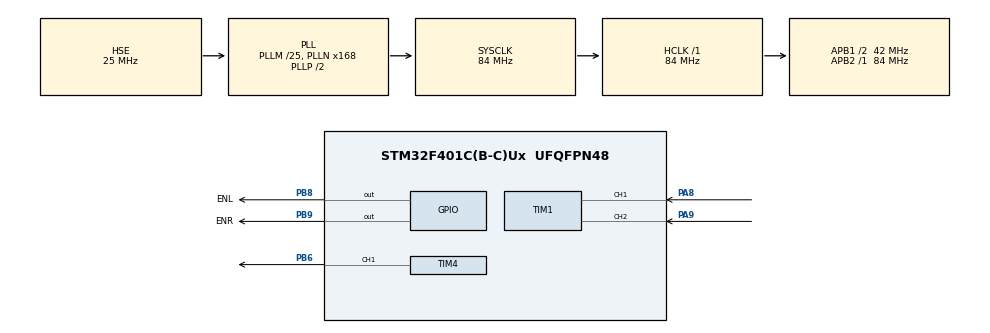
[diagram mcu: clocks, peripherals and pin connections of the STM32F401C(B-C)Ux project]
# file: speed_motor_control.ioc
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Mcu.Family=STM32F4
RCC.PLLSourceVirtual=RCC_PLLSOURCE_HSE
TIM4.Channel-PWM\ Generation1\ CH1=TIM_CHANNEL_1
RCC.CortexFreq_Value=84000000
PB9.GPIO_Label=ENR
Dma.TIM4_CH1.0.FIFOMode=DMA_FIFOMODE_DISABLE
PH1\ -\ OSC_OUT.Mode=HSE-External-Oscillator
RCC.APB1CLKDivider=RCC_HCLK_DIV2
PA9.GPIO_PuPd=GPIO_PULLUP
RCC.SYSCLKSource=RCC_SYSCLKSOURCE_PLLCLK
ProjectManager.StackSize=0x400
Dma.TIM4_CH1.0.PeriphInc=DMA_PINC_DISABLE
TIM3.Channel-Input_Capture1_from_TRC=TIM_CHANNEL_1
PA13.Signal=SYS_JTMS-SWDIO
PB8.GPIO_Label=ENL
PH0\ -\ OSC_IN.Mode=HSE-External-Oscillator
SH.S_TIM1_CH1.0=TIM1_CH1,Encoder_Interface
PH0\ -\ OSC_IN.Signal=RCC_OSC_IN
ProjectManager.TargetToolchain=STM32CubeIDE
RCC.HCLKFreq_Value=84000000
RCC.APB2TimFreq_Value=84000000
TIM3.Period=0xffff
PA9.Signal=S_TIM1_CH2
PB6.Signal=S_TIM4_CH1
TIM4.Prescaler=200-1
Dma.TIM4_CH1.0.Priority=DMA_PRIORITY_MEDIUM
RCC.LSE_VALUE=32768
RCC.AHBFreq_Value=84000000
RCC.HSE_VALUE=25000000
PH1\ -\ OSC_OUT.Signal=RCC_OSC_OUT
board=custom
RCC.VCOOutputFreq_Value=168000000
NVIC.TIM3_IRQn=true\:0\:0\:false\:false\:true\:true\:true
TIM1.TIM_MasterOutputTrigger=TIM_TRGO_OC1
RCC.APB2Freq_Value=84000000
Dma.TIM4_CH1.0.Instance=DMA1_Stream0
Dma.TIM4_CH1.0.MemInc=DMA_MINC_ENABLE
SH.S_TIM1_CH2.0=TIM1_CH2,Encoder_Interface
PA14.Mode=Serial_Wire
TIM3.Prescaler=16-1
PA8.Signal=S_TIM1_CH1
VP_TIM3_VS_CH1.Mode=Input_Capture1_from_TRC
Dma.TIM4_CH1.0.Direction=DMA_PERIPH_TO_MEMORY
TIM4.Period=100
VP_TIM3_VS_ClockSourceITR.Mode=TriggerSource_ITR0
PA13.Mode=Serial_Wire
Mcu.Name=STM32F401C(B-C)Ux
RCC.48MHZClocksFreq_Value=42000000
RCC.SYSCLKFreq_VALUE=84000000
Mcu.Package=UFQFPN48
PB9.Signal=GPIO_Output
Dma.TIM4_CH1.0.Mode=DMA_NORMAL
PA14.Signal=SYS_JTCK-SWCLK
ProjectManager.HeapSize=0x200
RCC.HSI_VALUE=16000000
PA8.GPIO_PuPd=GPIO_PULLUP
VP_TIM4_VS_ClockSourceINT.Mode=Internal
NVIC.PriorityGroup=NVIC_PRIORITYGROUP_4
PB9.GPIO_Speed=GPIO_SPEED_FREQ_HIGH
RCC.PLLM=25
RCC.PLLN=168
SH.S_TIM4_CH1.0=TIM4_CH1,PWM Generation1 CH1
RCC.APB1TimFreq_Value=84000000
PA9.GPIO_Speed=GPIO_SPEED_FREQ_HIGH
PB8.Signal=GPIO_Output
NVIC.DMA1_Stream0_IRQn=true\:0\:0\:false\:false\:true\:false\:true
Dma.Request0=TIM4_CH1
VP_TIM3_VS_ControllerModeReset.Mode=Reset Mode
RCC.APB1Freq_Value=42000000
PB8.GPIO_Speed=GPIO_SPEED_FREQ_HIGH
Dma.TIM4_CH1.0.MemDataAlignment=DMA_MDATAALIGN_HALFWORD
PA8.GPIO_Speed=GPIO_SPEED_FREQ_HIGH
VP_TIM3_VS_ClockSourceINT.Mode=Internal
Dma.TIM4_CH1.0.PeriphDataAlignment=DMA_PDATAALIGN_HALFWORD

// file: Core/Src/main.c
/* USER CODE BEGIN Header */
/**
  ******************************************************************************
  * @file           : main.c
  * @brief          : Main program body
  ******************************************************************************
  * @attention
  *
  * <h2><center>&copy; Copyright (c) 2021 STMicroelectronics.
  * All rights reserved.</center></h2>
  *
  * This software component is licensed by ST under BSD 3-Clause license,
  * the "License"; You may not use this file except in compliance with the
  * License. You may obtain a copy of the License at:
  *                        opensource.org/licenses/BSD-3-Clause
  *
  ******************************************************************************
  */
/* USER CODE END Header */
#include "main.h"

TIM_HandleTypeDef htim1;
TIM_HandleTypeDef htim3;
TIM_HandleTypeDef htim4;
DMA_HandleTypeDef hdma_tim4_ch1;

/* USER CODE BEGIN PV */
volatile int16_t konter;
volatile uint8_t dir,valpwm=20;
volatile uint32_t trig;
volatile float freq;
/* USER CODE END PV */

void SystemClock_Config(void);
static void MX_GPIO_Init(void);
static void MX_DMA_Init(void);
static void MX_TIM1_Init(void);
static void MX_TIM3_Init(void);
static void MX_TIM4_Init(void);

int main(void)
{

  /* MCU Configuration--------------------------------------------------------*/

  /* Reset of all peripherals, Initializes the Flash interface and the Systick. */
  HAL_Init();

  /* Configure the system clock */
  SystemClock_Config();

  /* Initialize all configured peripherals */
  MX_GPIO_Init();
  MX_DMA_Init();
  MX_TIM1_Init();
  MX_TIM3_Init();
  MX_TIM4_Init();
  /* USER CODE BEGIN 2 */
HAL_TIM_Encoder_Start(&htim1, TIM_CHANNEL_ALL);
HAL_TIM_IC_Start_IT(&htim3, TIM_CHANNEL_1);
HAL_TIM_PWM_Start(&htim4, TIM_CHANNEL_1);
  /* USER CODE END 2 */

  /* Infinite loop */
  while (1)
  {

    /* USER CODE BEGIN 3 */
	  HAL_GPIO_WritePin(ENL_GPIO_Port, ENL_Pin, GPIO_PIN_RESET);
	  htim4.Instance->CCR1=valpwm;
	  konter = htim1.Instance->CNT;
	  dir = !(__HAL_TIM_IS_TIM_COUNTING_DOWN(&htim1));
  }
  /* USER CODE END 3 */
}

void SystemClock_Config(void)
{
  RCC_OscInitTypeDef RCC_OscInitStruct = {0};
  RCC_ClkInitTypeDef RCC_ClkInitStruct = {0};

  /** Configure the main internal regulator output voltage
  */
  __HAL_RCC_PWR_CLK_ENABLE();
  __HAL_PWR_VOLTAGESCALING_CONFIG(PWR_REGULATOR_VOLTAGE_SCALE2);
  /** Initializes the RCC Oscillators according to the specified parameters
  * in the RCC_OscInitTypeDef structure.
  */
  RCC_OscInitStruct.OscillatorType = RCC_OSCILLATORTYPE_HSE;
  RCC_OscInitStruct.HSEState = RCC_HSE_ON;
  RCC_OscInitStruct.PLL.PLLState = RCC_PLL_ON;
  RCC_OscInitStruct.PLL.PLLSource = RCC_PLLSOURCE_HSE;
  RCC_OscInitStruct.PLL.PLLM = 25;
  RCC_OscInitStruct.PLL.PLLN = 168;
  RCC_OscInitStruct.PLL.PLLP = RCC_PLLP_DIV2;
  RCC_OscInitStruct.PLL.PLLQ = 4;
  if (HAL_RCC_OscConfig(&RCC_OscInitStruct) != HAL_OK)
  {
    Error_Handler();
  }
  /** Initializes the CPU, AHB and APB buses clocks
  */
  RCC_ClkInitStruct.ClockType = RCC_CLOCKTYPE_HCLK|RCC_CLOCKTYPE_SYSCLK
                              |RCC_CLOCKTYPE_PCLK1|RCC_CLOCKTYPE_PCLK2;
  RCC_ClkInitStruct.SYSCLKSource = RCC_SYSCLKSOURCE_PLLCLK;
  RCC_ClkInitStruct.AHBCLKDivider = RCC_SYSCLK_DIV1;
  RCC_ClkInitStruct.APB1CLKDivider = RCC_HCLK_DIV2;
  RCC_ClkInitStruct.APB2CLKDivider = RCC_HCLK_DIV1;

  if (HAL_RCC_ClockConfig(&RCC_ClkInitStruct, FLASH_LATENCY_2) != HAL_OK)
  {
    Error_Handler();
  }
}

static void MX_TIM1_Init(void)
{

  TIM_Encoder_InitTypeDef sConfig = {0};
  TIM_MasterConfigTypeDef sMasterConfig = {0};

  htim1.Instance = TIM1;
  htim1.Init.Prescaler = 0;
  htim1.Init.CounterMode = TIM_COUNTERMODE_UP;
  htim1.Init.Period = 65535;
  htim1.Init.ClockDivision = TIM_CLOCKDIVISION_DIV1;
  htim1.Init.RepetitionCounter = 0;
  htim1.Init.AutoReloadPreload = TIM_AUTORELOAD_PRELOAD_DISABLE;
  sConfig.EncoderMode = TIM_ENCODERMODE_TI1;
  sConfig.IC1Polarity = TIM_ICPOLARITY_RISING;
  sConfig.IC1Selection = TIM_ICSELECTION_DIRECTTI;
  sConfig.IC1Prescaler = TIM_ICPSC_DIV1;
  sConfig.IC1Filter = 0;
  sConfig.IC2Polarity = TIM_ICPOLARITY_RISING;
  sConfig.IC2Selection = TIM_ICSELECTION_DIRECTTI;
  sConfig.IC2Prescaler = TIM_ICPSC_DIV1;
  sConfig.IC2Filter = 0;
  if (HAL_TIM_Encoder_Init(&htim1, &sConfig) != HAL_OK)
  {
    Error_Handler();
  }
  sMasterConfig.MasterOutputTrigger = TIM_TRGO_OC1;
  sMasterConfig.MasterSlaveMode = TIM_MASTERSLAVEMODE_DISABLE;
  if (HAL_TIMEx_MasterConfigSynchronization(&htim1, &sMasterConfig) != HAL_OK)
  {
    Error_Handler();
  }

}

static void MX_TIM3_Init(void)
{

  TIM_ClockConfigTypeDef sClockSourceConfig = {0};
  TIM_SlaveConfigTypeDef sSlaveConfig = {0};
  TIM_MasterConfigTypeDef sMasterConfig = {0};
  TIM_IC_InitTypeDef sConfigIC = {0};

  htim3.Instance = TIM3;
  htim3.Init.Prescaler = 16-1;
  htim3.Init.CounterMode = TIM_COUNTERMODE_UP;
  htim3.Init.Period = 0xffff;
  htim3.Init.ClockDivision = TIM_CLOCKDIVISION_DIV1;
  htim3.Init.AutoReloadPreload = TIM_AUTORELOAD_PRELOAD_DISABLE;
  if (HAL_TIM_Base_Init(&htim3) != HAL_OK)
  {
    Error_Handler();
  }
  sClockSourceConfig.ClockSource = TIM_CLOCKSOURCE_INTERNAL;
  if (HAL_TIM_ConfigClockSource(&htim3, &sClockSourceConfig) != HAL_OK)
  {
    Error_Handler();
  }
  if (HAL_TIM_IC_Init(&htim3) != HAL_OK)
  {
    Error_Handler();
  }
  sSlaveConfig.SlaveMode = TIM_SLAVEMODE_RESET;
  sSlaveConfig.InputTrigger = TIM_TS_ITR0;
  if (HAL_TIM_SlaveConfigSynchro(&htim3, &sSlaveConfig) != HAL_OK)
  {
    Error_Handler();
  }
  sMasterConfig.MasterOutputTrigger = TIM_TRGO_RESET;
  sMasterConfig.MasterSlaveMode = TIM_MASTERSLAVEMODE_DISABLE;
  if (HAL_TIMEx_MasterConfigSynchronization(&htim3, &sMasterConfig) != HAL_OK)
  {
    Error_Handler();
  }
  sConfigIC.ICPolarity = TIM_INPUTCHANNELPOLARITY_RISING;
  sConfigIC.ICSelection = TIM_ICSELECTION_TRC;
  sConfigIC.ICPrescaler = TIM_ICPSC_DIV1;
  sConfigIC.ICFilter = 0;
  if (HAL_TIM_IC_ConfigChannel(&htim3, &sConfigIC, TIM_CHANNEL_1) != HAL_OK)
  {
    Error_Handler();
  }

}

static void MX_TIM4_Init(void)
{

  TIM_ClockConfigTypeDef sClockSourceConfig = {0};
  TIM_MasterConfigTypeDef sMasterConfig = {0};
  TIM_OC_InitTypeDef sConfigOC = {0};

  htim4.Instance = TIM4;
  htim4.Init.Prescaler = 200-1;
  htim4.Init.CounterMode = TIM_COUNTERMODE_UP;
  htim4.Init.Period = 100;
  htim4.Init.ClockDivision = TIM_CLOCKDIVISION_DIV1;
  htim4.Init.AutoReloadPreload = TIM_AUTORELOAD_PRELOAD_DISABLE;
  if (HAL_TIM_Base_Init(&htim4) != HAL_OK)
  {
    Error_Handler();
  }
  sClockSourceConfig.ClockSource = TIM_CLOCKSOURCE_INTERNAL;
  if (HAL_TIM_ConfigClockSource(&htim4, &sClockSourceConfig) != HAL_OK)
  {
    Error_Handler();
  }
  if (HAL_TIM_PWM_Init(&htim4) != HAL_OK)
  {
    Error_Handler();
  }
  sMasterConfig.MasterOutputTrigger = TIM_TRGO_RESET;
  sMasterConfig.MasterSlaveMode = TIM_MASTERSLAVEMODE_DISABLE;
  if (HAL_TIMEx_MasterConfigSynchronization(&htim4, &sMasterConfig) != HAL_OK)
  {
    Error_Handler();
  }
  sConfigOC.OCMode = TIM_OCMODE_PWM1;
  sConfigOC.Pulse = 0;
  sConfigOC.OCPolarity = TIM_OCPOLARITY_HIGH;
  sConfigOC.OCFastMode = TIM_OCFAST_DISABLE;
  if (HAL_TIM_PWM_ConfigChannel(&htim4, &sConfigOC, TIM_CHANNEL_1) != HAL_OK)
  {
    Error_Handler();
  }
  HAL_TIM_MspPostInit(&htim4);

}

static void MX_DMA_Init(void)
{

  /* DMA controller clock enable */
  __HAL_RCC_DMA1_CLK_ENABLE();

  /* DMA interrupt init */
  /* DMA1_Stream0_IRQn interrupt configuration */
  HAL_NVIC_SetPriority(DMA1_Stream0_IRQn, 0, 0);
  HAL_NVIC_EnableIRQ(DMA1_Stream0_IRQn);

}

static void MX_GPIO_Init(void)
{
  GPIO_InitTypeDef GPIO_InitStruct = {0};

  /* GPIO Ports Clock Enable */
  __HAL_RCC_GPIOH_CLK_ENABLE();
  __HAL_RCC_GPIOA_CLK_ENABLE();
  __HAL_RCC_GPIOB_CLK_ENABLE();

  /*Configure GPIO pin Output Level */
  HAL_GPIO_WritePin(GPIOB, ENL_Pin|ENR_Pin, GPIO_PIN_RESET);

  /*Configure GPIO pins : ENL_Pin ENR_Pin */
  GPIO_InitStruct.Pin = ENL_Pin|ENR_Pin;
  GPIO_InitStruct.Mode = GPIO_MODE_OUTPUT_PP;
  GPIO_InitStruct.Pull = GPIO_NOPULL;
  GPIO_InitStruct.Speed = GPIO_SPEED_FREQ_HIGH;
  HAL_GPIO_Init(GPIOB, &GPIO_InitStruct);

}

void Error_Handler(void)
{
  __disable_irq();
  while (1)
  {
  }
}

/************************ (C) COPYRIGHT STMicroelectronics *****END OF FILE****/
